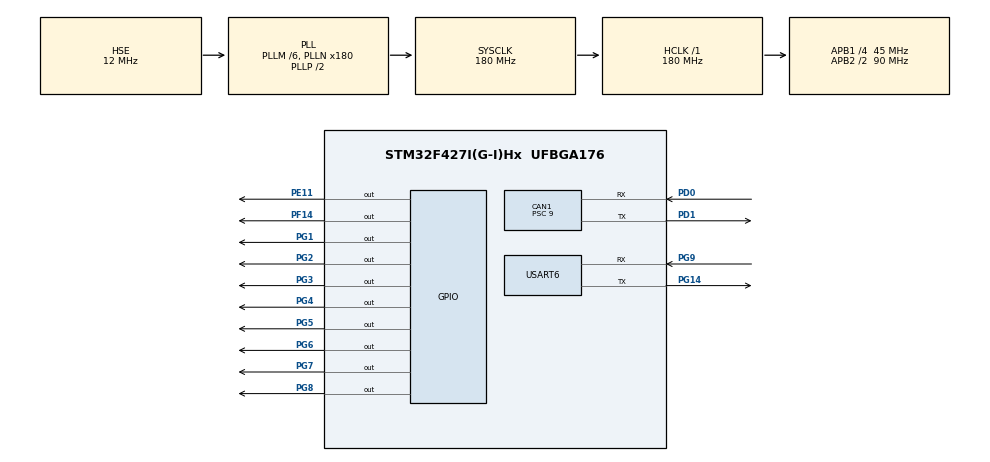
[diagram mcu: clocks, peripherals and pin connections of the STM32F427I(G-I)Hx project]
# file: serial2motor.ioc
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Mcu.Family=STM32F4
VP_SYS_VS_tim6.Mode=TIM6
RCC.CortexFreq_Value=180000000
PG6.Signal=GPIO_Output
NVIC.TIM6_DAC_IRQn=true\:0\:0\:false\:false\:true\:false\:false\:true
PG2.Signal=GPIO_Output
PG8.Signal=GPIO_Output
PG4.Signal=GPIO_Output
Dma.USART6_TX.0.Mode=DMA_NORMAL
Dma.USART6_RX.1.Direction=DMA_PERIPH_TO_MEMORY
RCC.SYSCLKSource=RCC_SYSCLKSOURCE_PLLCLK
ProjectManager.StackSize=0x400
Dma.USART6_TX.0.FIFOMode=DMA_FIFOMODE_DISABLE
Dma.USART6_TX.0.Direction=DMA_MEMORY_TO_PERIPH
PH0/OSC_IN.Mode=HSE-External-Oscillator
Dma.USART6_TX.0.Instance=DMA2_Stream6
Dma.USART6_RX.1.MemInc=DMA_MINC_ENABLE
Dma.USART6_RX.1.PeriphDataAlignment=DMA_PDATAALIGN_BYTE
RCC.HCLKFreq_Value=180000000
RCC.APB2TimFreq_Value=180000000
Dma.USART6_RX.1.Mode=DMA_NORMAL
PH1/OSC_OUT.Signal=RCC_OSC_OUT
PD0.Signal=CAN1_RX
Dma.USART6_RX.1.MemDataAlignment=DMA_MDATAALIGN_BYTE
RCC.AHBFreq_Value=180000000
RCC.HSE_VALUE=12000000
PG14.Mode=Asynchronous
PA14.Mode=Serial_Wire
VP_FREERTOS_VS_CMSIS_V1.Mode=CMSIS_V1
PH1/OSC_OUT.Mode=HSE-External-Oscillator
CAN1.Prescaler=9
Mcu.Package=UFBGA176
NVIC.TimeBase=TIM6_DAC_IRQn
USART6.VirtualMode=VM_ASYNC
NVIC.TimeBaseIP=TIM6
RCC.APB2CLKDivider=RCC_HCLK_DIV2
PF14.Signal=GPIO_Output
Dma.Request1=USART6_RX
RCC.APB1TimFreq_Value=90000000
Dma.USART6_RX.1.FIFOMode=DMA_FIFOMODE_DISABLE
Dma.USART6_TX.0.MemDataAlignment=DMA_MDATAALIGN_BYTE
Dma.Request0=USART6_TX
CAN1.CalculateTimeBit=1000.00
CAN1.CalculateTimeQuantum=200.0
Dma.USART6_RX.1.Instance=DMA2_Stream1
RCC.PLLSourceVirtual=RCC_PLLSOURCE_HSE
Dma.USART6_TX.0.MemInc=DMA_MINC_ENABLE
FREERTOS.Tasks01=defaultTask,0,128,StartDefaultTask,Default,NULL,Dynamic,NULL,NULL
PG7.Signal=GPIO_Output
PG3.Signal=GPIO_Output
PG1.Signal=GPIO_Output
PG5.Signal=GPIO_Output
PG9.Signal=USART6_RX
CAN1.CalculateBaudRate=1000000
PG9.Mode=Asynchronous
PD1.Signal=CAN1_TX
NVIC.DMA2_Stream1_IRQn=true\:5\:0\:false\:false\:true\:true\:false\:true
Dma.USART6_RX.1.PeriphInc=DMA_PINC_DISABLE
RCC.APB1CLKDivider=RCC_HCLK_DIV4
NVIC.USART6_IRQn=true\:5\:0\:false\:false\:true\:true\:true\:true
PA13.Signal=SYS_JTMS-SWDIO
CAN1.BS1=CAN_BS1_3TQ
ProjectManager.TargetToolchain=STM32CubeIDE
NVIC.DMA2_Stream6_IRQn=true\:0\:0\:false\:false\:true\:false\:false\:true
PE11.Signal=GPIO_Output
RCC.LSE_VALUE=32768
PG14.Signal=USART6_TX
board=custom
Dma.USART6_RX.1.Priority=DMA_PRIORITY_LOW
RCC.VCOOutputFreq_Value=360000000
PD1.Mode=CAN_Activate
PH0/OSC_IN.Signal=RCC_OSC_IN
RCC.APB2Freq_Value=90000000
Dma.USART6_TX.0.PeriphInc=DMA_PINC_DISABLE
PA13.Mode=Serial_Wire
Mcu.Name=STM32F427I(G-I)Hx
PD0.Mode=CAN_Activate
RCC.48MHZClocksFreq_Value=90000000
RCC.SYSCLKFreq_VALUE=180000000
PA14.Signal=SYS_JTCK-SWCLK
ProjectManager.HeapSize=0x200
RCC.HSI_VALUE=16000000
NVIC.PriorityGroup=NVIC_PRIORITYGROUP_4
RCC.PLLM=6
RCC.PLLN=180
Dma.USART6_TX.0.Priority=DMA_PRIORITY_LOW
RCC.APB1Freq_Value=45000000
NVIC.CAN1_RX0_IRQn=true\:5\:0\:false\:false\:true\:true\:true\:true
Dma.USART6_TX.0.PeriphDataAlignment=DMA_PDATAALIGN_BYTE

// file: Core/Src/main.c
/* USER CODE BEGIN Header */
/**
  ******************************************************************************
  * @file           : main.c
  * @brief          : Main program body
  ******************************************************************************
  * @attention
  *
  * <h2><center>&copy; Copyright (c) 2021 STMicroelectronics.
  * All rights reserved.</center></h2>
  *
  * This software component is licensed by ST under BSD 3-Clause license,
  * the "License"; You may not use this file except in compliance with the
  * License. You may obtain a copy of the License at:
  *                        opensource.org/licenses/BSD-3-Clause
  *
  ******************************************************************************
  */
/* USER CODE END Header */
#include "main.h"
#include "cmsis_os.h"
#include "can.h"
#include "dma.h"
#include "usart.h"
#include "gpio.h"

void SystemClock_Config(void);
void MX_FREERTOS_Init(void);

int main(void)
{

  /* MCU Configuration--------------------------------------------------------*/

  /* Reset of all peripherals, Initializes the Flash interface and the Systick. */
  HAL_Init();

  /* Configure the system clock */
  SystemClock_Config();

  /* Initialize all configured peripherals */
  MX_GPIO_Init();
  MX_DMA_Init();
  MX_CAN1_Init();
  MX_USART6_UART_Init();

  /* Call init function for freertos objects (in freertos.c) */
  MX_FREERTOS_Init();
  /* Start scheduler */
  osKernelStart();

  /* We should never get here as control is now taken by the scheduler */
  /* Infinite loop */
  while (1)
  {

  }
}

void SystemClock_Config(void)
{
  RCC_OscInitTypeDef RCC_OscInitStruct = {0};
  RCC_ClkInitTypeDef RCC_ClkInitStruct = {0};

  /** Configure the main internal regulator output voltage
  */
  __HAL_RCC_PWR_CLK_ENABLE();
  __HAL_PWR_VOLTAGESCALING_CONFIG(PWR_REGULATOR_VOLTAGE_SCALE1);
  /** Initializes the RCC Oscillators according to the specified parameters
  * in the RCC_OscInitTypeDef structure.
  */
  RCC_OscInitStruct.OscillatorType = RCC_OSCILLATORTYPE_HSE;
  RCC_OscInitStruct.HSEState = RCC_HSE_ON;
  RCC_OscInitStruct.PLL.PLLState = RCC_PLL_ON;
  RCC_OscInitStruct.PLL.PLLSource = RCC_PLLSOURCE_HSE;
  RCC_OscInitStruct.PLL.PLLM = 6;
  RCC_OscInitStruct.PLL.PLLN = 180;
  RCC_OscInitStruct.PLL.PLLP = RCC_PLLP_DIV2;
  RCC_OscInitStruct.PLL.PLLQ = 4;
  if (HAL_RCC_OscConfig(&RCC_OscInitStruct) != HAL_OK)
  {
    Error_Handler();
  }
  /** Activate the Over-Drive mode
  */
  if (HAL_PWREx_EnableOverDrive() != HAL_OK)
  {
    Error_Handler();
  }
  /** Initializes the CPU, AHB and APB buses clocks
  */
  RCC_ClkInitStruct.ClockType = RCC_CLOCKTYPE_HCLK|RCC_CLOCKTYPE_SYSCLK
                              |RCC_CLOCKTYPE_PCLK1|RCC_CLOCKTYPE_PCLK2;
  RCC_ClkInitStruct.SYSCLKSource = RCC_SYSCLKSOURCE_PLLCLK;
  RCC_ClkInitStruct.AHBCLKDivider = RCC_SYSCLK_DIV1;
  RCC_ClkInitStruct.APB1CLKDivider = RCC_HCLK_DIV4;
  RCC_ClkInitStruct.APB2CLKDivider = RCC_HCLK_DIV2;

  if (HAL_RCC_ClockConfig(&RCC_ClkInitStruct, FLASH_LATENCY_5) != HAL_OK)
  {
    Error_Handler();
  }
}

 /**
  * @brief  Period elapsed callback in non blocking mode
  * @note   This function is called  when TIM6 interrupt took place, inside
  * HAL_TIM_IRQHandler(). It makes a direct call to HAL_IncTick() to increment
  * a global variable "uwTick" used as application time base.
  * @param  htim : TIM handle
  * @retval None
  */
void HAL_TIM_PeriodElapsedCallback(TIM_HandleTypeDef *htim)
{
  if (htim->Instance == TIM6) {
    HAL_IncTick();
  }
}

void Error_Handler(void)
{
  __disable_irq();
  while (1)
  {
  }
}

/************************ (C) COPYRIGHT STMicroelectronics *****END OF FILE****/

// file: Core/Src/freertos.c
/* USER CODE BEGIN Header */
/**
  ******************************************************************************
  * File Name          : freertos.c
  * Description        : Code for freertos applications
  ******************************************************************************
  * @attention
  *
  * <h2><center>&copy; Copyright (c) 2021 STMicroelectronics.
  * All rights reserved.</center></h2>
  *
  * This software component is licensed by ST under Ultimate Liberty license
  * SLA0044, the "License"; You may not use this file except in compliance with
  * the License. You may obtain a copy of the License at:
  *                             www.st.com/SLA0044
  *
  ******************************************************************************
  */
/* USER CODE END Header */

#include "FreeRTOS.h"
#include "task.h"
#include "main.h"
#include "cmsis_os.h"

/* USER CODE BEGIN Includes */
#include "wtr_init.h"
#include "wtr_thread.h"
/* USER CODE END Includes */

osThreadId defaultTaskHandle;

void StartDefaultTask(void const * argument);

void MX_FREERTOS_Init(void); /* (MISRA C 2004 rule 8.1) */

/* GetIdleTaskMemory prototype (linked to static allocation support) */
void vApplicationGetIdleTaskMemory( StaticTask_t **ppxIdleTaskTCBBuffer, StackType_t **ppxIdleTaskStackBuffer, uint32_t *pulIdleTaskStackSize );

/* USER CODE BEGIN GET_IDLE_TASK_MEMORY */
static StaticTask_t xIdleTaskTCBBuffer;
static StackType_t xIdleStack[configMINIMAL_STACK_SIZE];

void vApplicationGetIdleTaskMemory( StaticTask_t **ppxIdleTaskTCBBuffer, StackType_t **ppxIdleTaskStackBuffer, uint32_t *pulIdleTaskStackSize )
{
  *ppxIdleTaskTCBBuffer = &xIdleTaskTCBBuffer;
  *ppxIdleTaskStackBuffer = &xIdleStack[0];
  *pulIdleTaskStackSize = configMINIMAL_STACK_SIZE;
  /* place for user code */
}
/* USER CODE END GET_IDLE_TASK_MEMORY */

void MX_FREERTOS_Init(void) {
  /* USER CODE BEGIN Init */
  wtr_init();
  /* USER CODE END Init */

  /* Create the thread(s) */
  /* definition and creation of defaultTask */
  osThreadDef(defaultTask, StartDefaultTask, osPriorityNormal, 0, 128);
  defaultTaskHandle = osThreadCreate(osThread(defaultTask), NULL);

  /* USER CODE BEGIN RTOS_THREADS */
  /* add threads, ... */
  wtr_AddThreads();
  /* USER CODE END RTOS_THREADS */

}

void StartDefaultTask(void const * argument)
{
  for(;;)
  {
    osDelay(1);
  }
}

/************************ (C) COPYRIGHT STMicroelectronics *****END OF FILE****/
